AUTOSAR XML (schema 00052)
package /apd/AdaptiveApplicationSwComponentTypes
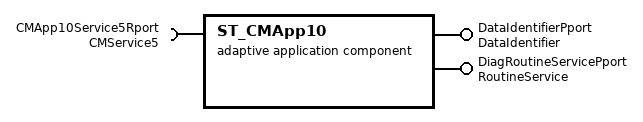
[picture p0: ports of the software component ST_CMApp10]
  adaptive application sw component type ST_CMApp10
    require port CMApp10Service5Rport: required-interface=CMService5
    provide port DataIdentifierPport: provided-interface=DataIdentifier
    provide port DiagRoutineServicePport: provided-interface=RoutineService
package /apd/Executables
  executable ST_CMApp10: category=APPLICATION_LEVEL, minimum-timer-granularity=1000.0
    root sw component prototype ST_CMApp10Root: application-type=ST_CMApp10
